# ATmega8515 device description
Architecture: AVR8; Family: megaAVR
Programming and debug interfaces: ISP, HVPP
Registers are 8-bit, access not given, no defined reset value unless marked. A register's access mark holds for its fields unless they carry their own. Offsets are from the block's base; lines under a group give offsets from that group; [hi:lo] are bit positions; {n}, {i} and the like mark numbered series; 'fields as' and 'values as' point back to an identical list; <NAME> marks a mode.

## Ordering variants
standard: 2.7 to 5.5 V

## Memory
prog space: start 0x0000 size 0x2000, little endian
  0x0000 FLASH size 0x2000 flash, rw, executable, page 0x40
  0x1f00 BOOT_SECTION_1 size 0x0100 flash, rw, executable, page 0x40
  0x1e00 BOOT_SECTION_2 size 0x0200 flash, rw, executable, page 0x40
  0x1c00 BOOT_SECTION_3 size 0x0400 flash, rw, executable, page 0x40
  0x1800 BOOT_SECTION_4 size 0x0800 flash, rw, executable, page 0x40
signatures space: start 0 size 3, little endian
  0 SIGNATURES size 3 signatures, ro
fuses space: start 0 size 0x0002, little endian
  0 FUSES size 0x0002 fuses, rw
lockbits space: start 0 size 0x0001, little endian
  0 LOCKBITS size 0x0001 lockbits, rw
data space: start 0x0000 size 0x10000, little endian
  0x0000 REGISTERS size 0x0020 regs
  0x0020 MAPPED_IO size 0x0040 io
  0x0060 IRAM size 0x0200 ram
  0x0260 XRAM size 0xfda0 ram, external
eeprom space: start 0x0000 size 0x0200, little endian
  0x0000 EEPROM size 0x0200 eeprom, rw, page 0x04
io space: start 0x00 size 0x40, little endian
osccal space: start 0 size 4, little endian
  0 OSCCAL size 4 osccal, ro

## Peripheral instances (address, pins/pin function, parameters)
AC at 0x00 — Analog Comparator
USART at 0x00
SPI at 0x00 — Serial Peripheral Interface
CPU at 0x00 — CPU Registers
  parameters: CORE_VERSION=V2E
EXINT at 0x00 — External Interrupts
WDT at 0x00 — Watchdog Timer
TC0 at 0x00 — Timer/Counter, 8-bit
TC1 at 0x00 — Timer/Counter, 16-bit
PORTA at 0x00 — I/O Port
PORTB at 0x00 — I/O Port
PORTC at 0x00 — I/O Port
PORTD at 0x00 — I/O Port
PORTE at 0x00 — I/O Port
EEPROM at 0x00
FUSE at 0 in fuses — Fuses
LOCKBIT at 0 in lockbits — Lockbits

## Interrupts
0 RESET — External Reset, Power-on Reset and Watchdog Reset
1 INT0 — External Interrupt Request 0
2 INT1 — External Interrupt Request 1
3 TIMER1_CAPT — Timer/Counter1 Capture Event
4 TIMER1_COMPA — Timer/Counter1 Compare Match A
5 TIMER1_COMPB — Timer/Counter1 Compare MatchB
6 TIMER1_OVF — Timer/Counter1 Overflow
7 TIMER0_OVF — Timer/Counter0 Overflow
8 SPI_STC — Serial Transfer Complete
9 USART_RX — USART, Rx Complete
10 USART_UDRE — USART Data Register Empty
11 USART_TX — USART, Tx Complete
12 ANA_COMP — Analog Comparator
13 INT2 — External Interrupt Request 2
14 TIMER0_COMP — Timer 0 Compare Match
15 EE_RDY — EEPROM Ready
16 SPM_RDY — Store Program Memory Ready

## Properties
SIGNATURES: SIGNATURE0=0x1e, SIGNATURE1=0x93, SIGNATURE2=0x06

## LOCKBIT — Lockbits
Instances: LOCKBIT 0 in lockbits
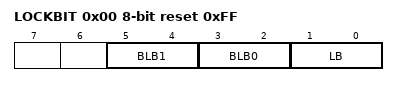
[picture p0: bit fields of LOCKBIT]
0x00 LOCKBIT reset 0xFF
  [5:4] BLB1 — Boot Loader Protection Mode
    0=LPM_SPM_DISABLE (LPM and SPM prohibited in Boot Section); 1=LPM_DISABLE (LPM prohibited in Boot Section); 2=SPM_DISABLE (SPM prohibited in Boot Section); 3=NO_LOCK (No lock on SPM and LPM in Boot Section)
  [3:2] BLB0 — Boot Loader Protection Mode
    0=LPM_SPM_DISABLE (LPM and SPM prohibited in Application Section); 1=LPM_DISABLE (LPM prohibited in Application Section); 2=SPM_DISABLE (SPM prohibited in Application Section); 3=NO_LOCK (No lock on SPM and LPM in Application Section)
  [1:0] LB — Memory Lock
    0=PROG_VER_DISABLED (Further programming and verification disabled); 2=PROG_DISABLED (Further programming disabled); 3=NO_LOCK (No memory lock features enabled)

## AC — Analog Comparator
Instances: AC 0x00
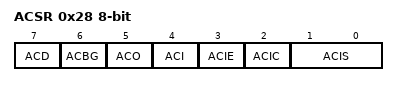
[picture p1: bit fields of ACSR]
0x28 ACSR — Analog Comparator Control And Status Register
  [7] ACD — Analog Comparator Disable
  [6] ACBG — Analog Comparator Bandgap Select
  [5] ACO — Analog Compare Output
  [4] ACI — Analog Comparator Interrupt Flag
  [3] ACIE — Analog Comparator Interrupt Enable
  [2] ACIC — Analog Comparator Input Capture Enable
  [1:0] ACIS — Analog Comparator Interrupt Mode Select bits
    0=Interrupt on Toggle; 2=Interrupt on Falling Edge; 3=Interrupt on Rising Edge
